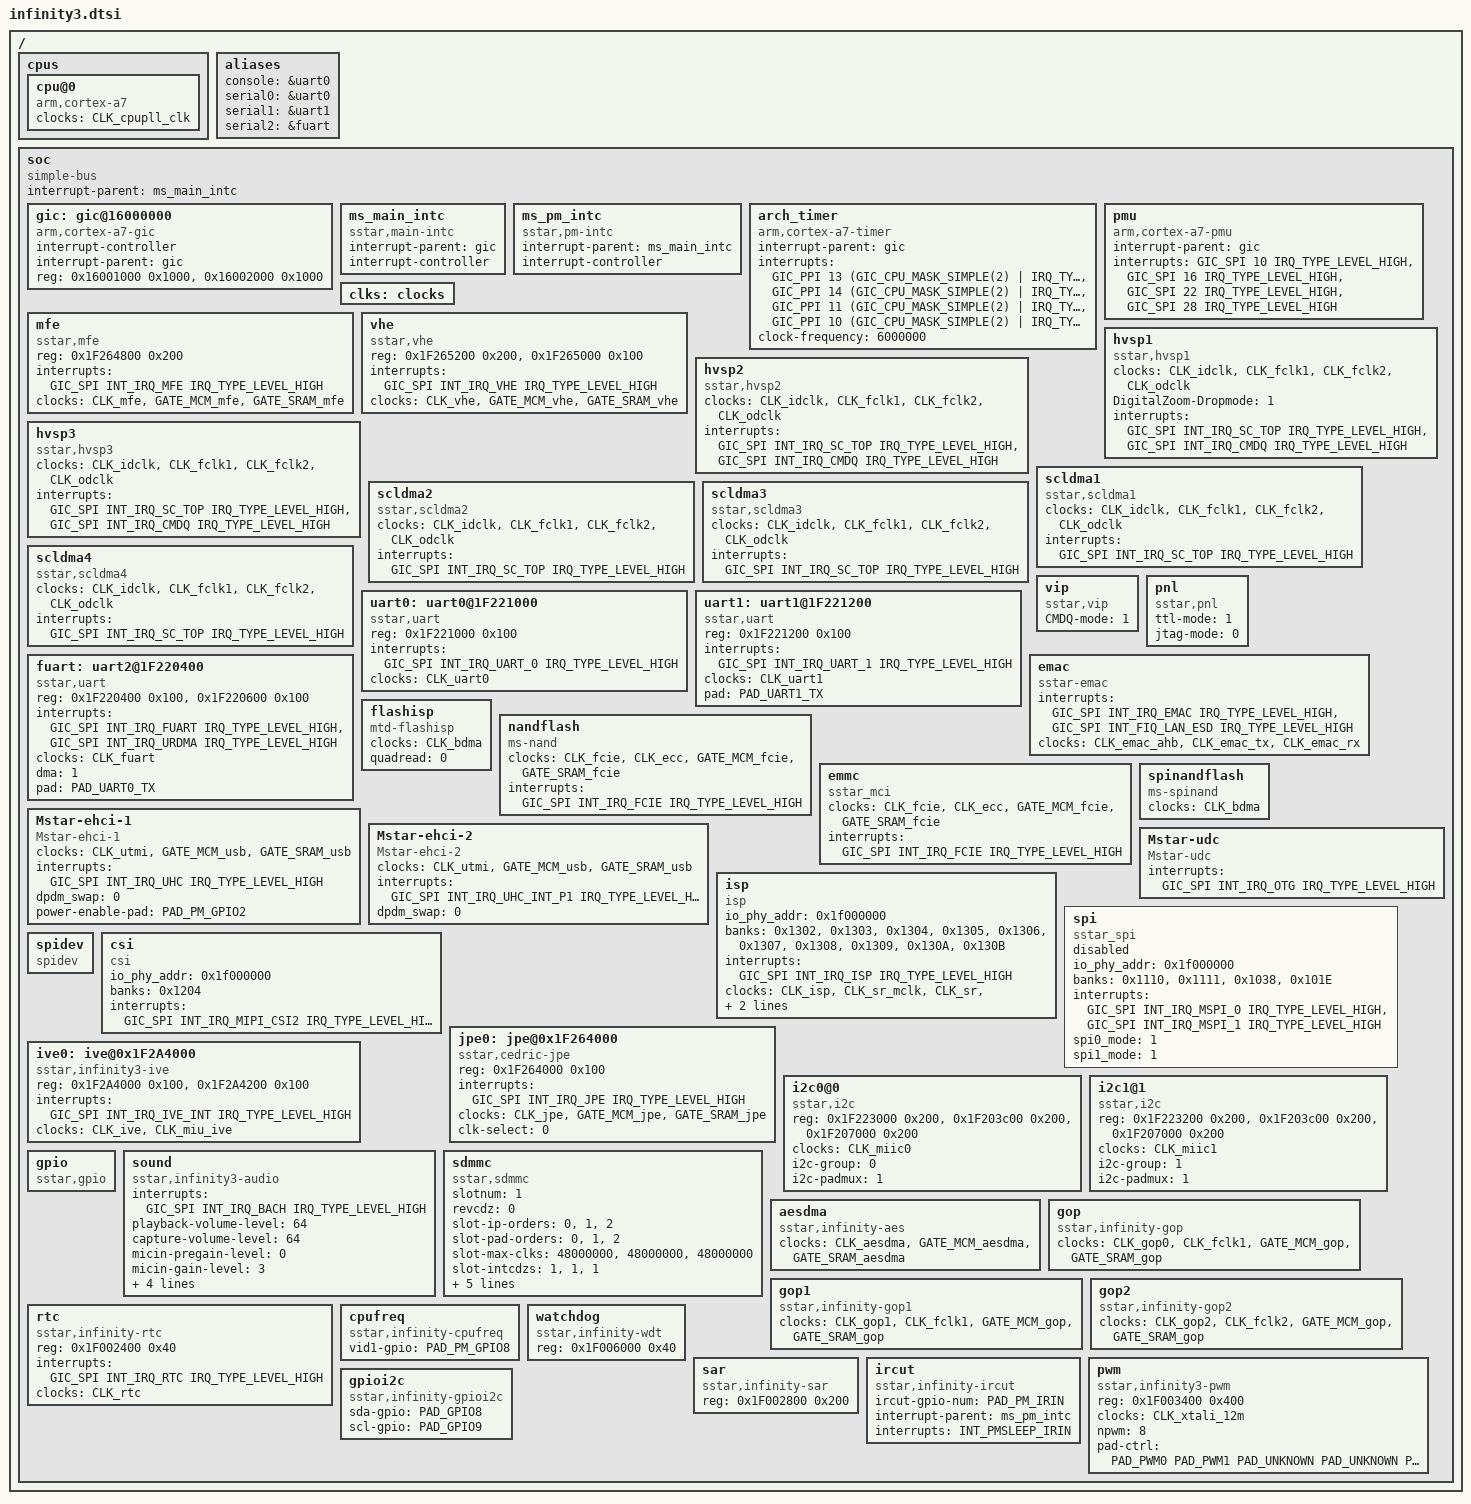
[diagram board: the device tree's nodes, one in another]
/*
* infinity3.dtsi- Sigmastar
*
* Copyright (c) [2019~2020] SigmaStar Technology.
*
*
* This software is licensed under the terms of the GNU General Public
* License version 2, as published by the Free Software Foundation, and
* may be copied, distributed, and modified under those terms.
*
* This program is distributed in the hope that it will be useful,
* but WITHOUT ANY WARRANTY; without even the implied warranty of
* MERCHANTABILITY or FITNESS FOR A PARTICULAR PURPOSE.  See the
* GNU General Public License version 2 for more details.
*
*/

#include <../../../../drivers/sstar/include/infinity3/irqs.h>
#include <../../../../drivers/sstar/include/infinity3/gpio.h>
#include <dt-bindings/interrupt-controller/irq.h>
#include <dt-bindings/interrupt-controller/arm-gic.h>
#include "skeleton.dtsi"


/ {
    cpus {
        #address-cells = <1>;
        #size-cells = <0>;

        cpu@0 {
            device_type = "cpu";
            compatible = "arm,cortex-a7";
            clocks = <&CLK_cpupll_clk>;
        };
    };

    aliases {
        console = &uart0;
        serial0 = &uart0;
        serial1 = &uart1;
        serial2 = &fuart;
    };

    soc {
        compatible = "simple-bus";
        interrupt-parent = <&ms_main_intc>;
        #address-cells = <1>;
        #size-cells = <1>;
        ranges;

        gic: gic@16000000 {
            compatible = "arm,cortex-a7-gic";
            #interrupt-cells = <3>;
            #address-cells = <1>;
            #size-cells = <1>;
            interrupt-controller;
            interrupt-parent = <&gic>;
            reg = <0x16001000 0x1000>,
                  <0x16002000 0x1000>;
        };

        ms_main_intc: ms_main_intc {
            compatible = "sstar,main-intc";
            #interrupt-cells = <3>;
            #address-cells = <1>;
            #size-cells = <1>;
            interrupt-parent=<&gic>;
            interrupt-controller;
        };

        ms_pm_intc: ms_pm_intc {
            compatible = "sstar,pm-intc";
            #interrupt-cells = <1>;
            interrupt-parent=<&ms_main_intc>;
            interrupt-controller;
        };


        arch_timer {
            compatible = "arm,cortex-a7-timer", "arm,armv7-timer";
            interrupt-parent=<&gic>;
            interrupts = <GIC_PPI 13 (GIC_CPU_MASK_SIMPLE(2) | IRQ_TYPE_LEVEL_LOW)>,
                         <GIC_PPI 14 (GIC_CPU_MASK_SIMPLE(2) | IRQ_TYPE_LEVEL_LOW)>,
                         <GIC_PPI 11 (GIC_CPU_MASK_SIMPLE(2) | IRQ_TYPE_LEVEL_LOW)>,
                         <GIC_PPI 10 (GIC_CPU_MASK_SIMPLE(2) | IRQ_TYPE_LEVEL_LOW)>;
            clock-frequency = <6000000>;
        };

        pmu {
            compatible = "arm,cortex-a7-pmu";
            interrupt-parent=<&gic>;
            interrupts = <GIC_SPI 10 IRQ_TYPE_LEVEL_HIGH>,
                         <GIC_SPI 16 IRQ_TYPE_LEVEL_HIGH>,
                         <GIC_SPI 22 IRQ_TYPE_LEVEL_HIGH>,
                         <GIC_SPI 28 IRQ_TYPE_LEVEL_HIGH>;
        };

        clks: clocks{
            #address-cells = <1>;
            #size-cells = <1>;
            ranges;
        };

/*
        timer_clockevent: timer@1F006040 {
            compatible = "sstar,piu-clockevent";
            reg = <0x1F006040 0x100>;
            interrupts=<GIC_SPI INT_FIQ_TIMER_0 IRQ_TYPE_LEVEL_HIGH>;
            clocks = <&CLK_xtali_12m>;
        };
*/
        mfe: mfe {
            compatible = "sstar,mfe";
            reg = <0x1F264800 0x200>;
            interrupts=<GIC_SPI INT_IRQ_MFE IRQ_TYPE_LEVEL_HIGH>;
            clocks = <&CLK_mfe>,<&GATE_MCM_mfe>, <&GATE_SRAM_mfe>;
            clock-names = "CKG_mfe";
            status = "ok";
        };

        vhe: vhe {
            compatible = "sstar,vhe";
            reg = <0x1F265200 0x200>,<0x1F265000 0x100>;
            interrupts=<GIC_SPI INT_IRQ_VHE IRQ_TYPE_LEVEL_HIGH>;
            clocks = <&CLK_vhe>,<&GATE_MCM_vhe>, <&GATE_SRAM_vhe>;
            clock-names = "CKG_vhe";
            status = "ok";
        };

        hvsp1: hvsp1 {
            compatible = "sstar,hvsp1";
            //reg = <0x1F000000 0x100>;
            //clk,chiptop,hvsp0,sc0,dnr,ldc
            clocks = <&CLK_idclk>,<&CLK_fclk1>,<&CLK_fclk2>,<&CLK_odclk>;
            clock-names = "CLK_idclk","CLK_fclk1","CLK_fclk2","CLK_odclk";
            status = "ok";
            DigitalZoom-Dropmode = <1>;
            interrupts = <GIC_SPI INT_IRQ_SC_TOP IRQ_TYPE_LEVEL_HIGH>, <GIC_SPI INT_IRQ_CMDQ IRQ_TYPE_LEVEL_HIGH>;
        };

        hvsp2: hvsp2 {
            compatible = "sstar,hvsp2";
            //reg = <0x1F000000 0x100>;
            //clk,chiptop,hvsp0,sc0,dnr,ldc
            clocks = <&CLK_idclk>,<&CLK_fclk1>,<&CLK_fclk2>,<&CLK_odclk>;
            clock-names = "CLK_idclk","CLK_fclk1","CLK_fclk2","CLK_odclk";
            status = "ok";
            interrupts = <GIC_SPI INT_IRQ_SC_TOP IRQ_TYPE_LEVEL_HIGH>, <GIC_SPI INT_IRQ_CMDQ IRQ_TYPE_LEVEL_HIGH>;
        };

        hvsp3: hvsp3 {
            compatible = "sstar,hvsp3";
            //reg = <0x1F000000 0x100>;
            //clk,chiptop,hvsp0,sc0,dnr,ldc
            clocks = <&CLK_idclk>,<&CLK_fclk1>,<&CLK_fclk2>,<&CLK_odclk>;
            clock-names = "CLK_idclk","CLK_fclk1","CLK_fclk2","CLK_odclk";
            status = "ok";
            interrupts = <GIC_SPI INT_IRQ_SC_TOP IRQ_TYPE_LEVEL_HIGH>, <GIC_SPI INT_IRQ_CMDQ IRQ_TYPE_LEVEL_HIGH>;
        };

        scldma1: scldma1 {
            compatible = "sstar,scldma1";
            //reg = <0x1F000000 0x100>;
            //clk,chiptop,scldma
            clocks =  <&CLK_idclk>,<&CLK_fclk1>,<&CLK_fclk2>,<&CLK_odclk>;
            clock-names = "CLK_idclk","CLK_fclk1","CLK_fclk2","CLK_odclk";
            status = "ok";
            interrupts = <GIC_SPI INT_IRQ_SC_TOP IRQ_TYPE_LEVEL_HIGH>;
        };
        scldma2: scldma2 {
            compatible = "sstar,scldma2";
            //reg = <0x1F000000 0x100>;
            //clk,chiptop,scldma
            clocks =  <&CLK_idclk>,<&CLK_fclk1>,<&CLK_fclk2>,<&CLK_odclk>;
            clock-names = "CLK_idclk","CLK_fclk1","CLK_fclk2","CLK_odclk";
            status = "ok";
            interrupts = <GIC_SPI INT_IRQ_SC_TOP IRQ_TYPE_LEVEL_HIGH>;
        };
        scldma3: scldma3 {
            compatible = "sstar,scldma3";
            //reg = <0x1F000000 0x100>;
            //clk,chiptop,scldma
            clocks =  <&CLK_idclk>,<&CLK_fclk1>,<&CLK_fclk2>,<&CLK_odclk>;
            clock-names = "CLK_idclk","CLK_fclk1","CLK_fclk2","CLK_odclk";
            status = "ok";
            interrupts = <GIC_SPI INT_IRQ_SC_TOP IRQ_TYPE_LEVEL_HIGH>;
        };
        scldma4: scldma4 {
            compatible = "sstar,scldma4";
            //reg = <0x1F000000 0x100>;
            //clk,chiptop,scldma
            clocks =  <&CLK_idclk>,<&CLK_fclk1>,<&CLK_fclk2>,<&CLK_odclk>;
            clock-names = "CLK_idclk","CLK_fclk1","CLK_fclk2","CLK_odclk";
            status = "ok";
            interrupts = <GIC_SPI INT_IRQ_SC_TOP IRQ_TYPE_LEVEL_HIGH>;
        };

        vip: vip {
            compatible = "sstar,vip";
            status = "ok";
            CMDQ-mode = <1>;
            //reg = <0x1F224000 0x200>;
        };

        pnl: pnl {
            compatible = "sstar,pnl";
            status = "ok";
            ttl-mode = <1>;
            jtag-mode = <0>;
            //Reg = <0x1F224000 0x200>;
        };

        uart0: uart0@1F221000 {
            compatible = "sstar,uart";
            reg = <0x1F221000 0x100>;
            interrupts = <GIC_SPI INT_IRQ_UART_0 IRQ_TYPE_LEVEL_HIGH>;
            clocks = <&CLK_uart0>;
            status = "ok";
        };
        uart1: uart1@1F221200 {
            compatible = "sstar,uart";
            reg = <0x1F221200 0x100>;
            interrupts = <GIC_SPI INT_IRQ_UART_1 IRQ_TYPE_LEVEL_HIGH>;
            clocks = <&CLK_uart1>;
            pad = <PAD_UART1_TX>;
            //pad = <PAD_FUART_RTS>;
            //pad = <PAD_GPIO6>;
            status = "ok";
        };
        fuart: uart2@1F220400 {
            compatible = "sstar,uart";
            reg = <0x1F220400 0x100>, <0x1F220600 0x100>;
            interrupts = <GIC_SPI INT_IRQ_FUART IRQ_TYPE_LEVEL_HIGH>, <GIC_SPI INT_IRQ_URDMA IRQ_TYPE_LEVEL_HIGH>;
            clocks = <&CLK_fuart>;
            dma = <1>;
            pad = <PAD_UART0_TX>;
            //pad = <PAD_FUART_TX>;
            //pad = <PAD_GPIO4>;
            status = "ok";
        };

        emac {
            compatible = "sstar-emac";
            interrupts = <GIC_SPI INT_IRQ_EMAC IRQ_TYPE_LEVEL_HIGH>, <GIC_SPI INT_FIQ_LAN_ESD IRQ_TYPE_LEVEL_HIGH>;
            clocks = <&CLK_emac_ahb>,<&CLK_emac_tx>,<&CLK_emac_rx>;
            //led-orange = <PAD_SPI0_DI>; //software toggle GPIO LED For QFN
            //led-green = <PAD_SPI0_DO>;  //software toggle GPIO LED For QFN
			status = "ok";
        };

        flashisp {
            compatible = "mtd-flashisp";
            clocks = <&CLK_bdma>;
            quadread = <0>;
            status = "ok";
        };

        nandflash {
            compatible = "ms-nand";
            clocks =<&CLK_fcie>, <&CLK_ecc>, <&GATE_MCM_fcie>, <&GATE_SRAM_fcie>;
            interrupts =  <GIC_SPI INT_IRQ_FCIE IRQ_TYPE_LEVEL_HIGH>;
            status = "ok";
        };

		emmc {
            compatible = "sstar_mci";
            clocks =<&CLK_fcie>, <&CLK_ecc>, <&GATE_MCM_fcie>, <&GATE_SRAM_fcie>;
            interrupts =  <GIC_SPI INT_IRQ_FCIE IRQ_TYPE_LEVEL_HIGH>;
            status = "ok";
        };


        spinandflash {
            compatible = "ms-spinand";
            clocks =<&CLK_bdma>;
            status = "ok";
        };

        Mstar-ehci-1 {
            compatible = "Mstar-ehci-1";
            clocks = <&CLK_utmi>, <&GATE_MCM_usb>, <&GATE_SRAM_usb>;
            interrupts = <GIC_SPI INT_IRQ_UHC IRQ_TYPE_LEVEL_HIGH>;
            dpdm_swap=<0>;
            power-enable-pad = <PAD_PM_GPIO2>; //PAD_SPI0_CK
            status = "ok";
        };

        Mstar-ehci-2 {
            compatible = "Mstar-ehci-2";
            clocks = <&CLK_utmi>, <&GATE_MCM_usb>, <&GATE_SRAM_usb>;
            interrupts = <GIC_SPI INT_IRQ_UHC_INT_P1 IRQ_TYPE_LEVEL_HIGH>;
            dpdm_swap=<0>;
            status = "ok";
        };

        Mstar-udc {
            compatible = "Mstar-udc";
            interrupts = <GIC_SPI INT_IRQ_OTG IRQ_TYPE_LEVEL_HIGH>;
            status = "ok";
        };

        isp: isp {
            compatible = "isp";
            io_phy_addr = <0x1f000000>;
            banks = <0x1302>,<0x1303>,<0x1304>,<0x1305>,<0x1306>,<0x1307>,<0x1308>,<0x1309>,<0x130A>,<0x130B>;
            interrupts = <GIC_SPI INT_IRQ_ISP IRQ_TYPE_LEVEL_HIGH>;
            clocks = <&CLK_isp>,<&CLK_sr_mclk>,<&CLK_sr>,<&CLK_csi_mac>;
            status = "ok";
            clk-pad = <PAD_SR_IO17>;
            //clk-pad = <PAD_SPI0_CK>; //be compatible with the previous QFN, so it must reserved 4 pins for SPI0 pads
            //isp-flag = <0>;
        };
        spi: spi {
            compatible = "sstar_spi";
            io_phy_addr = <0x1f000000>;
            banks = <0x1110>,<0x1111>,<0x1038>,<0x101E>;
            interrupts = <GIC_SPI INT_IRQ_MSPI_0 IRQ_TYPE_LEVEL_HIGH>,<GIC_SPI INT_IRQ_MSPI_1 IRQ_TYPE_LEVEL_HIGH>;
            spi0_mode = <1>;
            spi1_mode = <1>;
            status = "disabled";
        };
        spidev: spidev {
            compatible = "spidev";
        };
        csi: csi {
            compatible = "csi";
            io_phy_addr = <0x1f000000>;
            banks = <0x1204>;
            interrupts = <GIC_SPI INT_IRQ_MIPI_CSI2 IRQ_TYPE_LEVEL_HIGH>;
            status = "ok";
        };

        jpe0: jpe@0x1F264000 {
            compatible = "sstar,cedric-jpe";
            reg = <0x1F264000 0x100>;
            interrupts = <GIC_SPI INT_IRQ_JPE IRQ_TYPE_LEVEL_HIGH>;
            clocks = <&CLK_jpe>,<&GATE_MCM_jpe>, <&GATE_SRAM_jpe>;
            clock-names = "CKG_jpe";
            clk-select = <0>; // 0: 288MHz  1: 216MHz  2: 54MHz  3: 27MHz
            status = "ok";
        };

        ive0: ive@0x1F2A4000 {
            compatible = "sstar,infinity3-ive";
            reg = <0x1F2A4000 0x100>,<0x1F2A4200 0x100>;
            interrupts = <GIC_SPI INT_IRQ_IVE_INT IRQ_TYPE_LEVEL_HIGH>;
            clocks = <&CLK_ive>,<&CLK_miu_ive>;
            status = "ok";
        };

        i2c0@0{
            compatible = "sstar,i2c";
            reg = <0x1F223000 0x200>,<0x1F203c00 0x200>,<0x1F207000 0x200>;
                #address-cells = <1>;
                #size-cells = <0>;
            clocks = <&CLK_miic0>;
            i2c-group = <0>;
            status = "ok";
            /*
             * padmux: 1 -> PAD_I2C0_SCL, PAD_I2C0_SDA
             *         2 -> PAD_PWM0, PAD_PWM1
             *         3 -> PAD_SR_IO00, PAD_SR_IO01
            */
            i2c-padmux = <1>;
        };

        i2c1@1{
            compatible = "sstar,i2c";
            reg = <0x1F223200 0x200>,<0x1F203c00 0x200>,<0x1F207000 0x200>;
                #address-cells = <1>;
                #size-cells = <0>;
            clocks = <&CLK_miic1>;
            i2c-group = <1>;
            /*
             * padmux: 1 -> PAD_I2C1_SCL, PAD_I2C1_SDA
             *         2 -> PAD_PWM0, PAD_PWM1
             *         3 -> PAD_SR_IO00, PAD_SR_IO01
            */
            i2c-padmux = <1>;
            status = "ok";
//            24c512@54 {
//                compatible = "sstar,24c512";
//                reg = <0x54>;
//            };
        };


        gpio:gpio{
            compatible = "sstar,gpio";
        };

        sound {
            compatible = "sstar,infinity3-audio";
//            reg = <0x1F000000 0x1000000>;
            interrupts=<GIC_SPI INT_IRQ_BACH IRQ_TYPE_LEVEL_HIGH>;
            playback-volume-level=<64>;    //0~94
            capture-volume-level=<64>;
           // micin-pregain-level=<1>;    //0~3
            micin-pregain-level=<0>;    //0~3
            micin-gain-level=<3>;    //0~7
            linein-gain-level=<2>;  //0~7
            amp-gpio = <PAD_PM_GPIO1  1>;
            clocks = <&CLK_upll_384m>, <&GATE_MCM_bach>, <&GATE_SRAM_bach>;
           // playback-dma-buffer=<98304>; //512(ms)*48(kHz)*2(ch)*2(16bits)
           // capture-dma-buffer=<122880>; //640(ms)*48(kHz)*2(ch)*2(16bits)
            status = "ok";
        };

        sdmmc {
            compatible = "sstar,sdmmc";

            slotnum = <1>;
            revcdz = <0>;

            slot-ip-orders = <0>,<1>,<2>;
            slot-pad-orders = <0>,<1>,<2>;
            slot-max-clks = <48000000>,<48000000>,<48000000>;
	           slot-intcdzs = <1>,<1>,<1>;
	           slot-fakecdzs = <0>,<0>,<0>;
            slot-pwr-gpios = <19>,<0>,<0>;

            clocks = <&CLK_sdio>,<&GATE_MCM_sdio>,<&GATE_SRAM_sdio>,<&CLK_fcie>,<&GATE_MCM_fcie>,<&GATE_SRAM_fcie>;
            status = "ok";
        };

        aesdma {
            compatible = "sstar,infinity-aes";
            clocks = <&CLK_aesdma>,<&GATE_MCM_aesdma>, <&GATE_SRAM_aesdma>;
            status = "ok";
        };

        gop{
            compatible = "sstar,infinity-gop";
            clocks = <&CLK_gop0>,<&CLK_fclk1>,<&GATE_MCM_gop>, <&GATE_SRAM_gop>;
            status = "ok";
        };

        gop1{
            compatible = "sstar,infinity-gop1";
            clocks = <&CLK_gop1>,<&CLK_fclk1>,<&GATE_MCM_gop>, <&GATE_SRAM_gop>;
            status = "ok";
        };

        gop2{
            compatible = "sstar,infinity-gop2";
            clocks = <&CLK_gop2>,<&CLK_fclk2>,<&GATE_MCM_gop>, <&GATE_SRAM_gop>;
            status = "ok";
        };

        rtc {
            compatible = "sstar,infinity-rtc";
            reg = <0x1F002400 0x40>;
            interrupts=<GIC_SPI INT_IRQ_RTC IRQ_TYPE_LEVEL_HIGH>;
            clocks = <&CLK_rtc>;
            status = "ok";
        };

        cpufreq {
            compatible = "sstar,infinity-cpufreq";
//            vid0-gpio = <PAD_PM_GPIO7>;
            vid1-gpio = <PAD_PM_GPIO8>;
            status = "ok";
        };

        watchdog: watchdog {
            compatible = "sstar,infinity-wdt";
            reg = <0x1F006000 0x40>;
            status = "ok";
        };

        sar: sar {
            compatible = "sstar,infinity-sar";
            reg = <0x1F002800 0x200>;
            status = "ok";
        };

        ircut {
            compatible = "sstar,infinity-ircut";
            ircut-gpio-num = <PAD_PM_IRIN>;///PM_GPIO_IRIN
            interrupt-parent = <&ms_pm_intc>;
            interrupts = <INT_PMSLEEP_IRIN>;
            status = "ok";
        };

        pwm {
            compatible = "sstar,infinity3-pwm";
            reg = <0x1F003400 0x400>;
            clocks = <&CLK_xtali_12m>;
            npwm = <8>;
            pad-ctrl = <PAD_PWM0 PAD_PWM1 PAD_UNKNOWN PAD_UNKNOWN PAD_NAND_DA4 PAD_UNKNOWN PAD_UNKNOWN PAD_NAND_DA7>;
            status = "ok";
        };

        gpioi2c {
            compatible = "sstar,infinity-gpioi2c";
            sda-gpio = <PAD_GPIO8>;
            scl-gpio = <PAD_GPIO9>;
            status = "ok";
        };

		/*
		pm {
            compatible = "sstar,infinity-pm";
            interrupt-parent = <&ms_pm_intc>;
            interrupts = <INT_PMSLEEP_GPIO_0>;
            detect-gpio = <PAD_PM_GPIO0>;
        };
		*/
    };
};

&clks {
    #include <../../../../drivers/sstar/include/infinity3/reg_clks.h>
    #include "infinity3-clks.dtsi"
    #include "infinity3-gates.dtsi"
};

